# A34M41x register map
Vendor: ABOV Semiconductor Co., Ltd.; File version: 1.0
CPU: CM4 r0p1, little endian, MPU, FPU, VTOR, 4 interrupt priority bits
Registers are 32-bit, read-write, reset 0x0 unless marked. A register's access mark holds for its fields unless they carry their own. Offsets are from the block's base; [hi:lo] are bit positions; {n}, {i} and the like mark numbered series.

## CFMC — CODE FLASH MEMORY CONTROLLER
Base 0x41000000
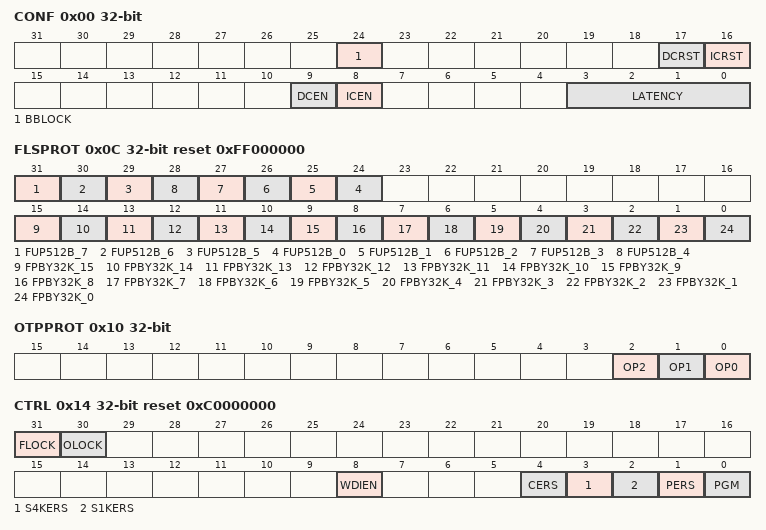
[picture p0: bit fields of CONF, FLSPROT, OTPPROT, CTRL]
0x00 CONF — Flash Memory Control Register
  [24] BBLOCK — Boot Block Lock Enable Bit
  [17] DCRST — Data Cache Reset Control bit (Auto Clear)
  [16] ICRST — Instruction Cache Reset Control Bit (Auto Clear)
  [9] DCEN — Data Cache Enable Bit
  [8] ICEN — Instruction Cache Enable Bit
  [3:0] LATENCY — Flash Wait Value Bits
0x04 FLSKEY — Flash Memory Access Key Register
  [31:0] FKEY — Flash Memory Access Key, KEY1(0x01234567) -> KEY2(0x12345678) -> KEY3(0x23456789)
0x08 OTPKEY — Flash OTP Access Key Register
  [31:0] OKEY — OTP Access Key Bits, KEY1(0x3456789A) -> KEY2(0x456789AB) -> KEY3(0x56789ABC)
0x0C FLSPROT reset 0xFF000000 — Flash Memory Protection Register
  [31] FUP512B_7 — Flash upper 4KB Unprotection, 0x0007_FE00 0x0007FFFF
  [30] FUP512B_6 — Flash upper 4KB Unprotection, 0x0007_FC00 0x0007FDFF
  [29] FUP512B_5 — Flash upper 4KB Unprotection, 0x0007_FA00 0x0007FBFF
  [n+24] FUP512B_{n} (n=0..4) — Flash upper 4KB Unprotection, 0x0007_F{200n:03} {0x7F1FF+0x200*n}
  [15] FPBY32K_15 — Flash 32KB Protection, 0x0007_8000 0x0007_FFFF
  [14] FPBY32K_14 — Flash 32KB Protection, 0x0007_0000 0x0007_7FFF
  [13] FPBY32K_13 — Flash 32KB Protection, 0x0006_8000 0x0006_FFFF
  [12] FPBY32K_12 — Flash 32KB Protection, 0x0006_0000 0x0006_7FFF
  [11] FPBY32K_11 — Flash 32KB Protection, 0x0005_8000 0x0005_FFFF
  [10] FPBY32K_10 — Flash 32KB Protection, 0x0005_0000 0x0005_7FFF
  [9] FPBY32K_9 — Flash 32KB Protection, 0x0004_8000 0x0004_FFFF
  [8] FPBY32K_8 — Flash 32KB Protection, 0x0004_0000 0x0004_7FFF
  [7] FPBY32K_7 — Flash 32KB Protection, 0x0003_8000 0x0003_FFFF
  [6] FPBY32K_6 — Flash 32KB Protection, 0x0003_0000 0x0003_7FFF
  [5] FPBY32K_5 — Flash 32KB Protection, 0x0002_8000 0x0002_FFFF
  [4] FPBY32K_4 — Flash 32KB Protection, 0x0002_0000 0x0002_7FFF
  [3] FPBY32K_3 — Flash 32KB Protection, 0x0001_8000 0x0001_FFFF
  [2] FPBY32K_2 — Flash 32KB Protection, 0x0001_0000 0x0001_7FFF
  [1] FPBY32K_1 — Flash 32KB Protection, 0x0000_8000 0x0000_FFFF
  [0] FPBY32K_0 — Flash 32KB Protection, 0x0000_0000 0x0000_7FFF
0x10 OTPPROT — Flash OTP Protection Register
  [2] OP2 — OTP Area Protection bit, 0x0F00_0400 0x0F00_05FF
  [1] OP1 — OTP Area Protection bit, 0x0F00_0200 0x0F00_03FF
  [0] OP0 — OTP Area Protection bit, 0x0F00_0000 0x0F00_01FF
0x14 CTRL reset 0xC0000000 — Flash Access Control Register
  [31] FLOCK — Flash Lock Setting Bit
  [30] OLOCK — OTP Lock Setting Bit
  [8] WDIEN — Write done interrupt enable bit
  [4] CERS — Chip Erase Mode Bit
  [3] S4KERS — Sector 4KB Erase Mode
  [2] S1KERS — Sector 1KB Erase Mode
  [1] PERS — Page Erase Mode
  [0] PGM — Program Mode
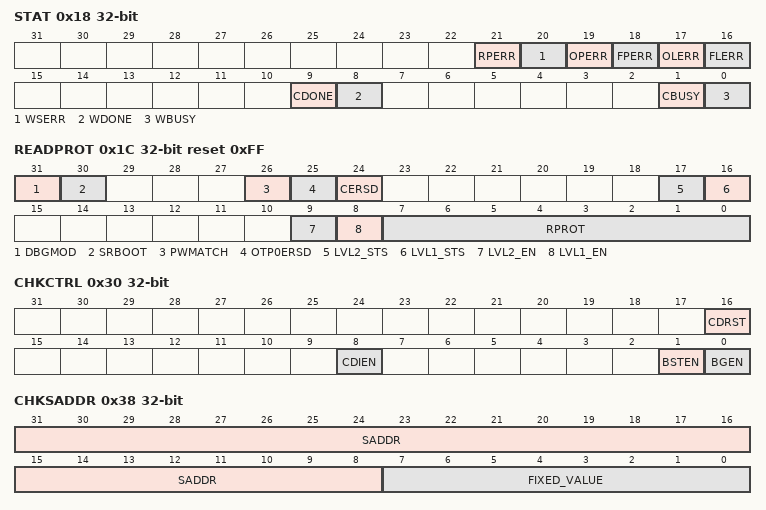
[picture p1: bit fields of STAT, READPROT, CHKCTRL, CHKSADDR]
0x18 STAT — Flash Access Status Register
  [21] RPERR — Read Protect Error(Auto Cleared)
  [20] WSERR — Write Sequence Error (Auto Cleared)
  [19] OPERR — OTP Protect Error (Auto Cleared)
  [18] FPERR — Flash Protect Error (Auto Cleared)
  [17] OLERR — OTP Lock Error (Auto Cleared)
  [16] FLERR — Flash Lock Error (Auto Cleared)
  [9] CDONE — Checksum Done Check (Auto Cleared)
  [8] WDONE — Write Done Check (Auto Cleared)
  [1] CBUSY ro — Checksum Busy Check
    0=Not Busy (Checksum Not Busy); 1=Busy (Checksum Busy)
  [0] WBUSY ro — Write Busy Check
    0=Not Busy (Checksum Not Busy); 1=Busy (Checksum Busy)
0x1C READPROT reset 0xFF — Flash Read Protection Register
  [31] DBGMOD ro — Debug Operating Status Bit
  [30] SRBOOT ro — Sram Boot Mode Status Bit
  [26] PWMATCH ro — Password Match Flag Bit
  [25] OTP0ERSD ro — Chip & OTP0 Erase Done Flag Bit
  [24] CERSD ro — Chip Erase Done Flag Bit
  [17] LVL2_STS ro — Protection Level 2 Status Bit (Raw Data)
  [16] LVL1_STS ro — Protection Level 1 Status Bit (Raw Data)
  [9] LVL2_EN ro — Protection Level 2 Enable Bit
  [8] LVL1_EN ro — Protection Level 1 Enable Bit
  [7:0] RPROT — Read Protection Control Bit
    255=Unprotection; 185=PROT_L1_PW (Protection Level 1 Password); 57=PROT_L1 (Protection Level 1); 128=PROT_L2_PW (Protection Level 2 Password); 0=PROT_L2 (Protection Level 2)
0x20 PWIN wo — Flash Read Protection Password Input Register
  [31:0] PWIN — Password Input Data Bit
0x30 CHKCTRL — Flash Checksum Control Register
  [16] CDRST — Checksum Data Reset (Auto Cleared)
    0=No Effect; 1=Reset
  [8] CDIEN — Checksum Done Interrupt
    0=Disable; 1=Enable
  [1] BSTEN — Burst Mode
    0=Disable; 1=Enable
  [0] BGEN — Back Ground Mode
    0=Disable; 1=Enable
0x34 CHKDOUT — Flash Checksum Data Output Register
  [15:0] CDOUT ro — Flash Checksum Data Output bit
0x38 CHKSADDR — Flash Checksum Start Address Resgister
  [31:8] SADDR — Flash Checksum Start Address bit
  [7:0] FIXED_VALUE ro — Fixed Vaule
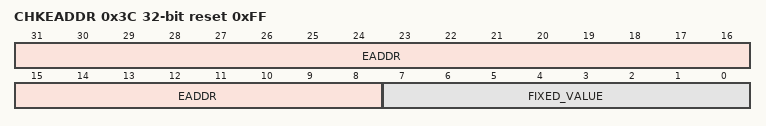
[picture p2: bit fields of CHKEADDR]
0x3C CHKEADDR reset 0xFF — Flash Checksum End Address Register
  [31:8] EADDR — Flash Checksum End Address bit
  [7:0] FIXED_VALUE ro
0xF18 PWPRST wo — Flash Read Protection Password Preset Register
  [31:0] PWPRST — Password Preset Data Bit
